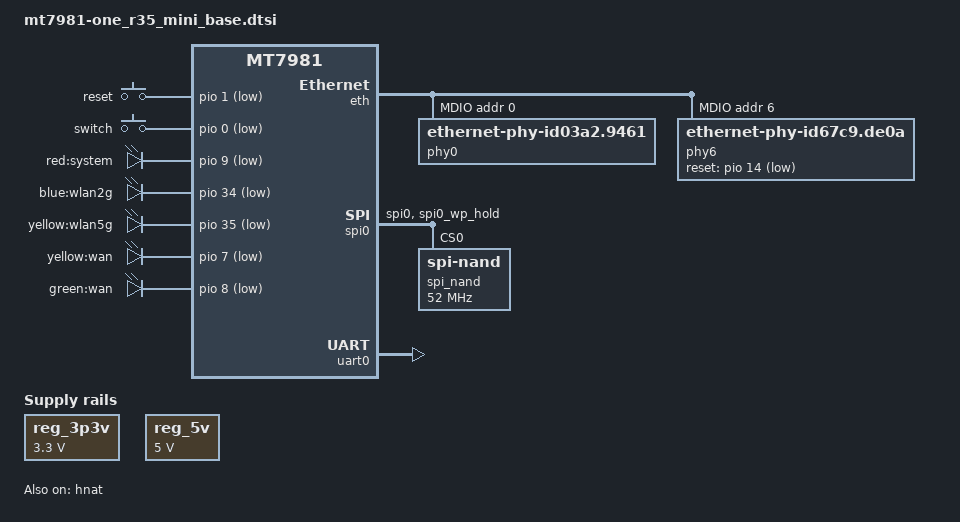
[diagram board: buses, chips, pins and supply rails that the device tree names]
// SPDX-License-Identifier: GPL-2.0-or-later OR MIT
/dts-v1/;

#include "mt7981.dtsi"

/ {
	compatible = "one,r35_mini-snand", "mediatek,mt7981";

	aliases {
		led-boot = &led_system_red;
		led-failsafe = &led_system_red;
		led-running = &led_system_red;
		
	};

	chosen {
		bootargs = "console=ttyS0,115200n1 loglevel=8 \
			    earlycon=uart8250,mmio32,0x11002000";
	};

	reg_3p3v: regulator-3p3v {
		compatible = "regulator-fixed";
		regulator-name = "fixed-3.3V";
		regulator-min-microvolt = <3300000>;
		regulator-max-microvolt = <3300000>;
		regulator-boot-on;
		regulator-always-on;
	};

	reg_5v: regulator-5v {
		compatible = "regulator-fixed";
		regulator-name = "fixed-5V";
		regulator-min-microvolt = <5000000>;
		regulator-max-microvolt = <5000000>;
		regulator-boot-on;
		regulator-always-on;
	};

	gpio-keys {
		compatible = "gpio-keys";

		reset {
			label = "reset";
			linux,code = <KEY_RESTART>;
			gpios = <&pio 1 GPIO_ACTIVE_LOW>;
		};

		switch {
			label = "switch";
			linux,code = <BTN_0>;
			linux,input-type = <EV_SW>;
			gpios = <&pio 0 GPIO_ACTIVE_LOW>;
		};
	};
	
	nmbm_spim_nand {
		compatible = "generic,nmbm";
		#address-cells = <1>;
		#size-cells = <1>;

		lower-mtd-device = <&spi_nand>;
		max-reserved-blocks = <32>;
		forced-create;

		partitions {
			compatible = "fixed-partitions";
			#address-cells = <1>;
			#size-cells = <1>;

			partition@0 {
				label = "BL2";
				reg = <0x0000000 0x0100000>;
				read-only;
			};

			partition@100000 {
				label = "u-boot-env";
				reg = <0x0100000 0x0080000>;
			};

			partition@180000 {
				label = "Factory";
				reg = <0x0180000 0x0200000>;
				read-only;
			};

			partition@380000 {
				label = "FIP";
				reg = <0x0380000 0x0200000>;
				read-only;
			};

			partition@580000 {
				label = "ubi";
				reg = <0x0580000 0x6E00000>;
			};
		};
	};

	leds {
		compatible = "gpio-leds";

		led_system_red: system_red {
			label = "red:system";
			gpios = <&pio 9 GPIO_ACTIVE_LOW>;
		};

		led-0 {
			label = "blue:wlan2g";
			gpios = <&pio 34 GPIO_ACTIVE_LOW>;
		};

		led-1 {
			label = "yellow:wlan5g";
			gpios = <&pio 35 GPIO_ACTIVE_LOW>;
		};

		led-2 {
			label = "yellow:wan";
			gpios = <&pio 7 GPIO_ACTIVE_LOW>;
		};

		led-3 {
			label = "green:wan";
			gpios = <&pio 8 GPIO_ACTIVE_LOW>;
		};

	};

};

&eth {
	status = "okay";

	gmac0: mac@0 {
		compatible = "mediatek,eth-mac";
		reg = <0>;
		phy-mode = "2500base-x";

		fixed-link {
			speed = <2500>;
			full-duplex;
			pause;
		};
	};

	gmac1: mac@1 {
		compatible = "mediatek,eth-mac";
		reg = <1>;
		phy-mode = "gmii";
		phy-handle = <&phy0>;
	};

	mdio: mdio-bus {
		#address-cells = <1>;
		#size-cells = <0>;

		phy0: phy@0 {
			compatible = "ethernet-phy-id03a2.9461";
			reg = <0>;
			nvmem-cells = <&phy_calibration>;
			nvmem-cell-names = "phy-cal-data";
		};

		phy6: phy@6 {
			compatible = "ethernet-phy-id67c9.de0a";
			reg = <6>;
			reset-gpios = <&pio 14 1>;
			reset-assert-us = <600>;
			reset-deassert-us = <20000>;
			phy-mode = "2500base-x";
		};
	};
};

&hnat {
	mtketh-wan = "eth1";
	mtketh-lan = "eth0";
	mtketh-max-gmac = <2>;
	ext-devices-prefix = "usb", "wwan","rmnet","eth2";
	status = "okay";
};

&spi0 {
	pinctrl-names = "default";
	pinctrl-0 = <&spi0_flash_pins>;
	status = "okay";

	spi_nand: spi_nand@0 {
		compatible = "spi-nand";
		#address-cells = <1>;
		#size-cells = <1>;
		reg = <0>;

		spi-max-frequency = <52000000>;
		spi-tx-bus-width = <4>;
		spi-rx-bus-width = <4>;

	};
};


&pio {

	spi0_flash_pins: spi0-pins {
		mux {
			function = "spi";
			groups = "spi0", "spi0_wp_hold";
		};

	};


	spic_pins: spi1-pins {
		mux {
			function = "spi";
			groups = "spi1_1";
		};
	};

	mmc0_pins_default: mmc0-pins-default {
		mux {
			function = "flash";
			groups = "emmc_45";
		};
	};
	mmc0_pins_uhs: mmc0-pins-uhs {
		mux {
			function = "flash";
			groups = "emmc_45";
		};
	};

};


&uart0 {
	status = "okay";
};

&mmc0 {
	pinctrl-names = "default", "state_uhs";
	pinctrl-0 = <&mmc0_pins_default>;
	pinctrl-1 = <&mmc0_pins_uhs>;
	bus-width = <4>;
	max-frequency = <3000000>;
	cap-sd-highspeed;
	vmmc-supply = <&reg_3p3v>;
	vqmmc-supply = <&reg_3p3v>;
	status = "disabled";
};
